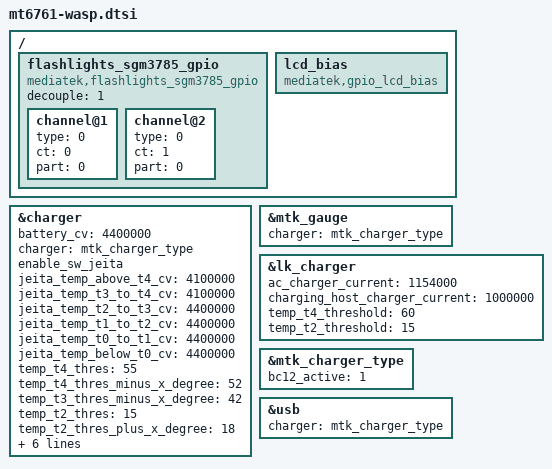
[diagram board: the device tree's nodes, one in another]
// SPDX-License-Identifier: GPL-2.0+
/*
 * Copyright (c) 2019 MediaTek Inc.
 *
 */

/delete-node/ &flashlights_mt6370;
/delete-node/ &mt6357_charger;

/ {
	flashlights_sgm3785_gpio: flashlights_sgm3785_gpio {
		compatible = "mediatek,flashlights_sgm3785_gpio";
		decouple = <1>;
		status = "okay";

		channel@1 {
			type = <0>;
			ct = <0>;
			part = <0>;
		};

		channel@2 {
			type = <0>;
			ct = <1>;
			part = <0>;
		};
	};

	lcd_bias: lcd_bias {
		compatible = "mediatek,gpio_lcd_bias";
		status = "okay";
	};
};

&charger {
	/* common */
	battery_cv = <4400000>;

	/* use external charger */
	charger = <&mtk_charger_type>;

	/* sw jeita */
	enable_sw_jeita;
	jeita_temp_above_t4_cv = <4100000>;
	jeita_temp_t3_to_t4_cv = <4100000>;
	jeita_temp_t2_to_t3_cv = <4400000>;
	jeita_temp_t1_to_t2_cv = <4400000>;
	jeita_temp_t0_to_t1_cv = <4400000>;
	jeita_temp_below_t0_cv = <4400000>;
	temp_t4_thres = <55>;
	temp_t4_thres_minus_x_degree = <52>;
	temp_t3_thres_minus_x_degree = <42>;
	temp_t2_thres = <15>;
	temp_t2_thres_plus_x_degree = <18>;
	temp_t1_thres_plus_x_degree = <3>;

	/* battery temperature protection */
	min_charge_temp_plus_x_degree = <3>;
	max_charge_temp = <60>;
	max_charge_temp_minus_x_degree = <57>;

	/* charging current */
	ac_charger_current = <1275000>;
	charging_host_charger_current = <1000000>;
};

&mtk_gauge {
	/* use external charger */
	charger = <&mtk_charger_type>;
};

&lk_charger {
	/delete-property/ enable_anime;
	/delete-property/ enable_pe_plus;
	/delete-property/ enable_pd20_reset;
	/delete-property/ power_path_support;

	/* charging current */
	ac_charger_current = <1154000>;
	charging_host_charger_current = <1000000>;

	/* battery temperature protection */
	temp_t4_threshold = <60>;
	temp_t2_threshold = <15>;
};

&mtk_charger_type {
	bc12_active = <1>;
};

&usb {
	/* use external charger */
	charger = <&mtk_charger_type>;
};

#include "mediatek/bat_setting/wasp_battery_prop.dtsi"
